VERSION ""

NS_ :

BS_:

BU_:
VAL_TABLE_ Drive_Overload 1 "Enable" 0 "Disable" ;
VAL_TABLE_ Sports_Mode 1 "Sports Mode Enable" 0 "Sports Mode Disable" ;
VAL_TABLE_ City_Mode 1 "City Mode Enable" 0 "City Mode Disable" ;
VAL_TABLE_ Fault_enable_Disable 1 "Enable" 0 "Disable" ;
VAL_TABLE_ Brake_Command 1 "Brake On" 0 "Brake Off" ;
VAL_TABLE_ Trip_reset 255 "Reset" 0 "Not reset" ;
VAL_TABLE_ eco_sports_mode 1 "sports mode" 0 "eco mode" ;
VAL_TABLE_ Invalid_BMS_data 3 "Regen current out of range" 2 "Drive current out of range" 1 "SOC out of range" ;
VAL_TABLE_ Vehicle_power_mode 2 "Sport" 1 "Eco" ;
VAL_TABLE_ Vehicle_status2 2 "MCU_ready" 1 "Low_bus_voltage" 0 "Regeneratio " ;
VAL_TABLE_ status 1 "Enable" 0 "Disable" ;
VAL_TABLE_ Vehicle_status 4 "Reverse" 2 "Forward" 1 "Park" 0 "Neutral" ;
VAL_TABLE_ Motor_Error 17 "Motor overspeed" 16 "Motor output phase loss" 15 "Rotary T/F Failure" 14 "Controller power undervoltage" 13 "Controller high temperature" 12 "Motor high temperature" 11 "Motor overload" 10 "Overcurrent" 9 "Open-circuit" 8 "Short-circuit" 7 "Undervoltage" 6 "Overvoltage" 5 "Self Inspection abnormality" 4 "Normal" 3 "Three level fault" 2 "Two level fault" 1 "One level fault" 0 "Normal" ;
VAL_TABLE_ Motor_Status 9 "Error" 8 "Normal" 7 "Get_Ready" 6 "Initialization" 5 "Reverse" 4 "Forward" 3 "Brake/Regen" 2 "Drive" 1 "Run" 0 "Stop" ;

BO_ 3221225472 VECTOR__INDEPENDENT_SIG_MSG: 0 Vector__XXX
 SG_ FAn_command : 0|8@1+ (1,0) [0|255] "" Vector__XXX
 SG_ Drive_overload : 0|1@1+ (1,0) [0|1] "" Vector__XXX
 SG_ MCU_Error_Code : 0|8@1+ (1,0) [0|255] "" Vector__XXX
 SG_ Invalid_BMS_data : 0|8@1+ (1,0) [0|255] "" Vector__XXX
 SG_ Vehicle_Power_mode : 0|8@1+ (1,0) [0|255] "" Vector__XXX
 SG_ FAN_Status : 0|1@1+ (1,0) [0|1] "" Vector__XXX
 SG_ DC_Current : 0|16@1- (1,0) [-32768|32767] "Adc" Vector__XXX
 SG_ Sports_mode : 0|1@1+ (1,0) [0|1] "" Vector__XXX
 SG_ City_Mode : 0|1@1+ (1,0) [0|1] "" Vector__XXX

BO_ 1801 New_Message_4: 8 Vector__XXX
 SG_ Fault_historic_details : 0|64@1+ (1,0) [0|255] "" Vector__XXX

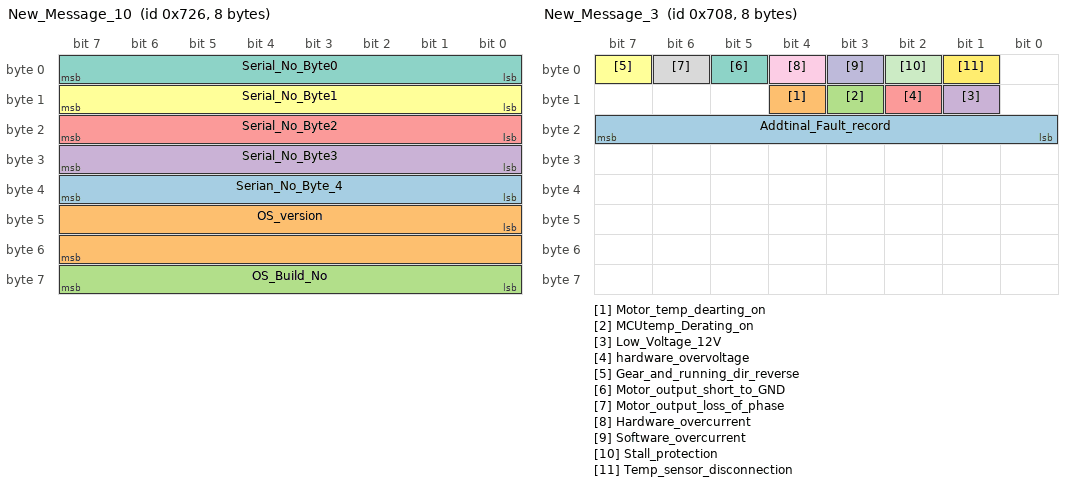
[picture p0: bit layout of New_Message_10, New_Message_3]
BO_ 1830 New_Message_10: 8 Vector__XXX
 SG_ Serian_No_Byte_4 : 32|8@1+ (1,0) [0|0] "" Vector__XXX
 SG_ OS_version : 40|16@1+ (1,0) [0|65535] "" Vector__XXX
 SG_ OS_Build_No : 56|8@1+ (1,0) [0|255] "" Vector__XXX
 SG_ Serial_No_Byte3 : 24|8@1+ (1,0) [0|255] "" Vector__XXX
 SG_ Serial_No_Byte2 : 16|8@1+ (1,0) [0|255] "" Vector__XXX
 SG_ Serial_No_Byte1 : 8|8@1+ (1,0) [0|255] "" Vector__XXX
 SG_ Serial_No_Byte0 : 0|8@1+ (1,0) [0|255] "" Vector__XXX

BO_ 1800 New_Message_3: 8 Vector__XXX
 SG_ Addtinal_Fault_record : 16|8@1+ (1,0) [0|255] "" Vector__XXX
 SG_ Motor_temp_dearting_on : 12|1@1+ (1,0) [0|1] "" Vector__XXX
 SG_ MCUtemp_Derating_on : 11|1@1+ (1,0) [0|1] "" Vector__XXX
 SG_ Low_Voltage_12V : 9|1@1+ (1,0) [0|1] "" Vector__XXX
 SG_ hardware_overvoltage : 10|1@1+ (1,0) [0|1] "" Vector__XXX
 SG_ Gear_and_running_dir_reverse : 7|1@1+ (1,0) [0|1] "" Vector__XXX
 SG_ Motor_output_short_to_GND : 5|1@1+ (1,0) [0|1] "" Vector__XXX
 SG_ Motor_output_loss_of_phase : 6|1@1+ (1,0) [0|1] "" Vector__XXX
 SG_ Hardware_overcurrent : 4|1@1+ (1,0) [0|1] "" Vector__XXX
 SG_ Software_overcurrent : 3|1@1+ (1,0) [0|1] "" Vector__XXX
 SG_ Stall_protection : 2|1@1+ (1,0) [0|1] "" Vector__XXX
 SG_ Temp_sensor_disconnection : 1|1@1+ (1,0) [0|1] "" Vector__XXX

BO_ 298 New_Message_11: 8 Vector__XXX
 SG_ DYN_Limit_I_IN : 0|16@1+ (0.1,0) [0|6553.5] "Amp" Vector__XXX
 SG_ DYN_LIM_I_OUT : 16|16@1+ (0.1,0) [0|6553.5] "Amp" Vector__XXX

BO_ 1828 New_Message_9: 8 Vector__XXX
 SG_ Motor_Torque_Estimated : 0|16@1- (0.1,0) [-3276.8|3276.7] "NM" Vector__XXX

BO_ 1815 New_Message_8: 8 Vector__XXX
 SG_ Operating_frequency : 0|16@1- (1,0) [-32768|32767] "Hz" Vector__XXX

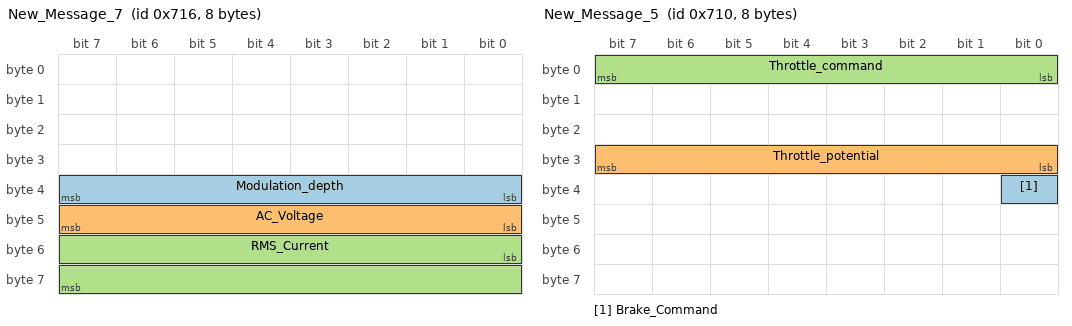
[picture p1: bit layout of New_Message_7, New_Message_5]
BO_ 1814 New_Message_7: 8 Vector__XXX
 SG_ Modulation_depth : 32|8@1+ (1,0) [0|0] "%" Vector__XXX
 SG_ AC_Voltage : 40|8@1+ (1,0) [0|255] "V rms" Vector__XXX
 SG_ RMS_Current : 48|16@1+ (1,0) [0|65535] "" Vector__XXX

BO_ 1808 New_Message_5: 8 Vector__XXX
 SG_ Brake_Command : 32|1@1+ (1,0) [0|1] "" Vector__XXX
 SG_ Throttle_potential : 24|8@1+ (0.1,0) [0|25.5] "" Vector__XXX
 SG_ Throttle_command : 0|8@1+ (1,0) [0|255] "%" Vector__XXX

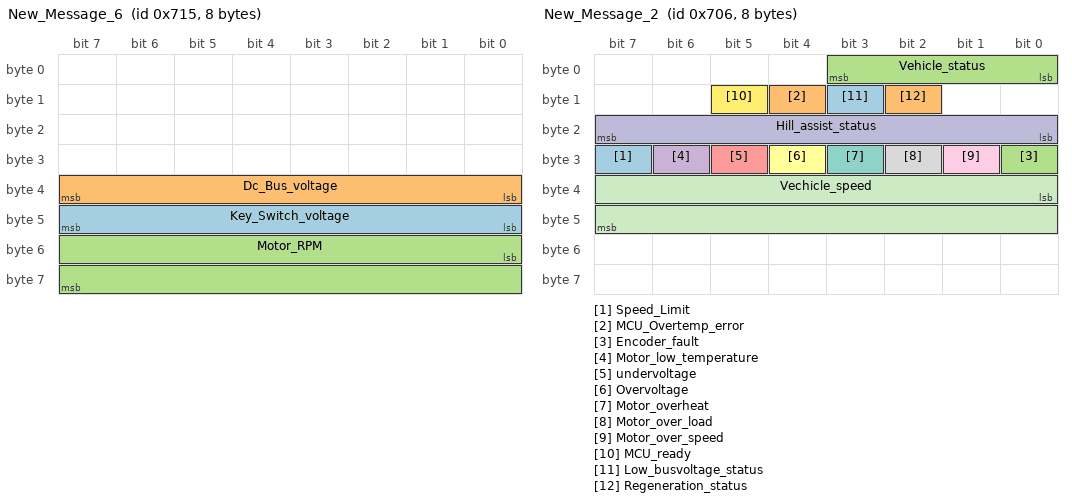
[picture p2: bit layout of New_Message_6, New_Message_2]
BO_ 1813 New_Message_6: 8 Vector__XXX
 SG_ Key_Switch_voltage : 40|8@1+ (1,0) [0|24] "" Vector__XXX
 SG_ Dc_Bus_voltage : 32|8@1+ (1,0) [0|255] "Volt" Vector__XXX
 SG_ Motor_RPM : 48|16@1+ (1,0) [0|65535] "" Vector__XXX

BO_ 1798 New_Message_2: 8 Vector__XXX
 SG_ Speed_Limit : 31|1@1+ (1,0) [0|1] "" Vector__XXX
 SG_ MCU_Overtemp_error : 12|1@1+ (1,0) [0|1] "" Vector__XXX
 SG_ Encoder_fault : 24|1@1+ (1,0) [0|1] "" Vector__XXX
 SG_ Motor_low_temperature : 30|1@1+ (1,0) [0|1] "" Vector__XXX
 SG_ undervoltage : 29|1@1+ (1,0) [0|1] "" Vector__XXX
 SG_ Overvoltage : 28|1@1+ (1,0) [0|1] "" Vector__XXX
 SG_ Motor_overheat : 27|1@1+ (1,0) [0|1] "" Vector__XXX
 SG_ Motor_over_load : 26|1@1+ (1,0) [0|1] "" Vector__XXX
 SG_ Motor_over_speed : 25|1@1+ (1,0) [0|0] "" Vector__XXX
 SG_ Hill_assist_status : 16|8@1+ (1,0) [0|255] "" Vector__XXX
 SG_ Vechicle_speed : 32|16@1- (0.1,0) [-3276.8|3276.7] "Kmph" Vector__XXX
 SG_ MCU_ready : 13|1@1+ (1,0) [0|1] "" Vector__XXX
 SG_ Low_busvoltage_status : 11|1@1+ (1,0) [0|0] "" Vector__XXX
 SG_ Regeneration_status : 10|1@1+ (1,0) [0|1] "" Vector__XXX
 SG_ Vehicle_status : 0|4@1+ (1,0) [0|15] "" Vector__XXX

BO_ 1797 New_Message_1: 8 Vector__XXX
 SG_ MCU_Temperature : 8|8@1+ (1,-50) [0|255] "" Vector__XXX
 SG_ Motor_Temperature : 0|8@1+ (1,-50) [0|255] "" Vector__XXX

CM_ BO_ 3221225472 "This is a message for not used signals, created by Vector CANdb++ DBC OLE DB Provider.";
BA_DEF_ SG_  "SigType" ENUM  "Default","Range","RangeSigned","ASCII","Discrete","Control","ReferencePGN","DTC","StringDelimiter","StringLength","StringLengthControl","MessageCounter","MessageChecksum";
BA_DEF_ SG_  "GenSigEVName" STRING ;
BA_DEF_ SG_  "GenSigILSupport" ENUM  "No","Yes";
BA_DEF_ SG_  "GenSigSendType" ENUM  "Cyclic","OnWrite","OnWriteWithRepetition","OnChange","OnChangeWithRepetition","IfActive","IfActiveWithRepetition","NoSigSendType";
BA_DEF_ SG_  "GenSigStartValue" INT 0 2147483647;
BA_DEF_ BO_  "GenMsgILSupport" ENUM  "No","Yes";
BA_DEF_ BU_  "NmStationAddress" INT 0 255;
BA_DEF_ BO_  "GenMsgSendType" ENUM  "cyclic","NotUsed","IfActive","NotUsed","NotUsed","NotUsed","NotUsed","NotUsed","noMsgSendType";
BA_DEF_ BO_  "GenMsgRequestable" INT 0 1;
BA_DEF_  "DBName" STRING ;
BA_DEF_  "BusType" STRING ;
BA_DEF_  "ProtocolType" STRING ;
BA_DEF_ BO_  "VFrameFormat" ENUM  "StandardCAN","ExtendedCAN","reserved","J1939PG";
BA_DEF_DEF_  "SigType" "Default";
BA_DEF_DEF_  "GenSigEVName" "Env@Nodename_@Signame";
BA_DEF_DEF_  "GenSigILSupport" "Yes";
BA_DEF_DEF_  "GenSigSendType" "NoSigSendType";
BA_DEF_DEF_  "GenSigStartValue" 0;
BA_DEF_DEF_  "GenMsgILSupport" "Yes";
BA_DEF_DEF_  "NmStationAddress" 254;
BA_DEF_DEF_  "GenMsgSendType" "noMsgSendType";
BA_DEF_DEF_  "GenMsgRequestable" 1;
BA_DEF_DEF_  "DBName" "";
BA_DEF_DEF_  "BusType" "CAN";
BA_DEF_DEF_  "ProtocolType" "J1939";
BA_DEF_DEF_  "VFrameFormat" "J1939PG";
BA_ "DBName" "D03CAN";
BA_ "VFrameFormat" BO_ 1801 0;
BA_ "VFrameFormat" BO_ 1830 0;
BA_ "VFrameFormat" BO_ 1800 0;
BA_ "VFrameFormat" BO_ 298 0;
BA_ "VFrameFormat" BO_ 1828 0;
BA_ "VFrameFormat" BO_ 1815 0;
BA_ "VFrameFormat" BO_ 1814 0;
BA_ "VFrameFormat" BO_ 1808 0;
BA_ "VFrameFormat" BO_ 1813 0;
BA_ "VFrameFormat" BO_ 1798 0;
BA_ "VFrameFormat" BO_ 1797 0;
BA_ "GenSigStartValue" SG_ 1797 MCU_Temperature 50;
BA_ "GenSigStartValue" SG_ 1797 Motor_Temperature 50;
VAL_ 3221225472 Drive_overload 1 "Enable" 0 "Disable" ;
VAL_ 3221225472 Invalid_BMS_data 3 "Regen current out of range" 2 "Drive current out of range" 1 "SOC out of range" ;
VAL_ 3221225472 Vehicle_Power_mode 2 "Sport" 1 "Eco" ;
VAL_ 3221225472 Sports_mode 1 "Sports Mode Enable" 0 "Sports Mode Disable" ;
VAL_ 3221225472 City_Mode 1 "City Mode Enable" 0 "City Mode Disable" ;
VAL_ 1800 Motor_temp_dearting_on 1 "Enable" 0 "Disable" ;
VAL_ 1800 MCUtemp_Derating_on 1 "Enable" 0 "Disable" ;
VAL_ 1800 Low_Voltage_12V 1 "Enable" 0 "Disable" ;
VAL_ 1800 Gear_and_running_dir_reverse 1 "Enable" 0 "Disable" ;
VAL_ 1800 Motor_output_short_to_GND 1 "Enable" 0 "Disable" ;
VAL_ 1800 Motor_output_loss_of_phase 1 "Enable" 0 "Disable" ;
VAL_ 1800 Hardware_overcurrent 1 "Enable" 0 "Disable" ;
VAL_ 1800 Software_overcurrent 1 "Enable" 0 "Disable" ;
VAL_ 1800 Stall_protection 1 "Enable" 0 "Disable" ;
VAL_ 1800 Temp_sensor_disconnection 1 "Enable" 0 "Disable" ;
VAL_ 1808 Brake_Command 1 "Brake On" 0 "Brake Off" ;
VAL_ 1798 Speed_Limit 1 "Enable" 0 "Disable" ;
VAL_ 1798 MCU_Overtemp_error 1 "Enable" 0 "Disable" ;
VAL_ 1798 Encoder_fault 1 "Enable" 0 "Disable" ;
VAL_ 1798 Motor_low_temperature 1 "Enable" 0 "Disable" ;
VAL_ 1798 undervoltage 1 "Enable" 0 "Disable" ;
VAL_ 1798 Overvoltage 1 "Enable" 0 "Disable" ;
VAL_ 1798 Motor_overheat 1 "Enable" 0 "Disable" ;
VAL_ 1798 Motor_over_load 1 "Enable" 0 "Disable" ;
VAL_ 1798 Motor_over_speed 1 "Enable" 0 "Disable" ;
VAL_ 1798 MCU_ready 1 "Enable" 0 "Disable" ;
VAL_ 1798 Low_busvoltage_status 1 "Enable" 0 "Disable" ;
VAL_ 1798 Regeneration_status 1 "Enable" 0 "Disable" ;
VAL_ 1798 Vehicle_status 8 "Forward(Sports Mode)" 4 "Reverse" 2 "Forward(City Mode)" 1 "Neutral" ;
